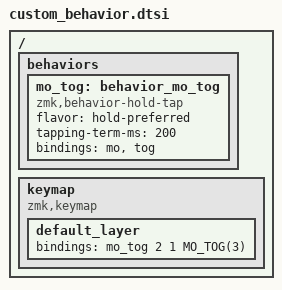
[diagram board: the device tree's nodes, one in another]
#include <dt-bindings/zmk/keys.h>
#include <behaviors.dtsi>

#define MO_TOG(layer) &mo_tog layer layer   // Macro to apply momentary-layer-on-hold/toggle-layer-on-tap to a specific layer

/ {
    behaviors {
        mo_tog: behavior_mo_tog {
            compatible = "zmk,behavior-hold-tap";
            #binding-cells = <2>;
            flavor = "hold-preferred";
            tapping-term-ms = <200>;
            bindings = <&mo>, <&tog>;
        };
    };

    keymap {
        compatible = "zmk,keymap";
        default_layer {
            bindings = <
                &mo_tog 2 1     // &mo 2 on hold, &tog 1 on tap
                MO_TOG(3)       // &mo 3 on hold, &tog 3 on tap
            >;
        };
    };
};
